# M05x_registers register map
File version: 0.1
CPU: 
Registers are 32-bit, read-write, reset 0x0 unless marked. A register's access mark holds for its fields unless they carry their own. Offsets are from the block's base; [hi:lo] are bit positions; lines under a group give offsets from that group; {n}, {i} and the like mark numbered series.

## CLK — Registers group
Base 0x50000200
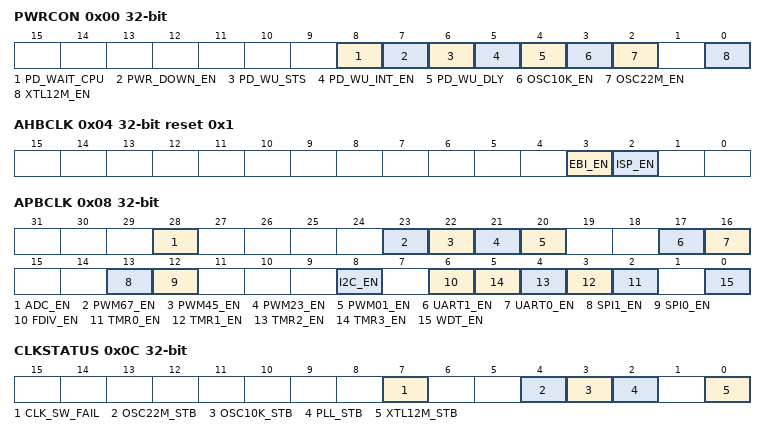
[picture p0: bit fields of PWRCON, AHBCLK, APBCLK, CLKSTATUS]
0x00 PWRCON (reset mask 0xFFFFFFF0) — System Power Down Control Register
  [8] PD_WAIT_CPU — This bit control the power down entry condition 1 = Chip entry power down mode when the both PWR_DOWN and CPU run WFI instruction. 0 = Chip entry power down mode when the PWR_DOWN bit is set to 1
  [7] PWR_DOWN_EN — System power down enable bit When set this bit "1", the chip power down mode is enabled and the chip power down active is depend on the PD_WAIT_CPU bit (a) if the PD_WAIT_CPU is "0" then the chip power down after the PWR_DOWN_EN bit set. (b) if the PD_WAIT_CPU is "1" then the chip keep active till the CPU sleep mode also active and then the chip power down When chip wake up from power down, this bit is auto cleared, user need to set this bit again for next power down. When in power down mode, external crystal (4~ 24MHz) and the 22.1184 MHz OSC will be disabled in this mode, but the 10 kHz OSC is not controlled by power down mode. When in power down mode, the PLL and system clock are disabled, and ignored the clock source selection. The clocks of peripheral are not controlled by power down mode, if the peripheral clock source is from 10 kHz oscillator. 1 = Chip enter the power down mode instant or wait CPU sleep command WFI 0 = Chip operate in normal mode or CPU in idle mode (sleep mode) because of WFI command
  [6] PD_WU_STS write-1-clears — Chip power down wake up status flag Set by "power down wake up", it indicates that resume from power down mode The flag is set if the GPIO(P0~P4), UART wakeup Write 1 to clear the bit Note: This bit is working only if PD_WU_INT_EN (PWRCON[5]) set to 1.
  [5] PD_WU_INT_EN — Power down mode wake Up Interrupt Enable 0 = Disable 1 = Enable. The interrupt will occur when Power down mode (Deep Sleep Mode) wakeup.
  [4] PD_WU_DLY — Enable the wake up delay counter. When the chip wakes up from power down mode, the clock control will delay certain clock cycles to wait system clock stable. The delayed clock cycle is 4096 clock cycles when chip work at external crystal (4 ~ 24MHz), and 256 clock cycles when chip work at 22.1184 MHz oscillator. 1 = Enable the clock cycle delay 0 = Disable the clock cycle delay
  [3] OSC10K_EN — Internal 10KHz Oscillator Control 1 = 10KHz Oscillation enable 0 = 10KHz Oscillation disable
  [2] OSC22M_EN — Internal 22.1184 MHz Oscillator Control 1 = 22.1184 MHz Oscillation enable 0 = 22.1184 MHz Oscillation disable
  [0] XTL12M_EN — External Crystal Oscillator Control The bit default value is set by flash controller user configuration register config0 [26:24]. When the default clock source is from external crystal. The bit is auto set to "1" 1 = Crystal oscillation enable 0 = Crystal oscillation disable
0x04 AHBCLK reset 0x1 — AHB Devices Clock Enable Control Register
  [3] EBI_EN — EBI Controller Clock Enable Control. 1 = To enable the EBI Controller clock. 0 = To disable the EBI Controller clock.
  [2] ISP_EN — Flash ISP Controller Clock Enable Control. 1 = To enable the Flash ISP controller clock. 0 = To disable the Flash ISP controller clock.
0x08 APBCLK (reset mask 0xFFFFFFF0) — APB Devices Clock Enable Control Register
  [28] ADC_EN — Analog-Digital-Converter (ADC) Clock Enable Control. 1 = Enable ADC clock 0 = Disable ADC clock
  [23] PWM67_EN — PWM_67 Clock Enable Control. 1 = Enable PWM67 clock 0 = Disable PWM67 clock
  [22] PWM45_EN — PWM_45 Clock Enable Control. 1 = Enable PWM45 clock 0 = Disable PWM45 clock
  [21] PWM23_EN — PWM_23 Clock Enable Control. 1 = Enable PWM23 clock 0 = Disable PWM23 clock
  [20] PWM01_EN — PWM_01 Clock Enable Control. 1 = Enable PWM01 clock 0 = Disable PWM01 clock
  [17] UART1_EN — UART1 Clock Enable Control. 1 = Enable UART1 clock 0 = Disable UART1 clock
  [16] UART0_EN — UART0 Clock Enable Control. 1 = Enable UART0 clock 0 = Disable UART0 clock
  [13] SPI1_EN — SPI1 Clock Enable Control. 0 = Disable SPI1 Clock 1 = Enable SPI1 Clock
  [12] SPI0_EN — SPI0 Clock Enable Control. 0 = Disable SPI0 Clock 1 = Enable SPI0 Clock
  [8] I2C_EN — I2C Clock Enable Control. 0 = Disable I2C Clock 1 = Enable I2C Clock
  [6] FDIV_EN — Clock Divider Clock Enable Control 0 = Disable FDIV Clock 1 = Enable FDIV Clock
  [n+2] TMR{n}_EN (n=0..3) — Timer{n} Clock Enable Control 0 = Disable Timer{n} Clock 1 = Enable Timer{n} Clock
  [0] WDT_EN — Watch Dog Timer Clock Enable. This bit is the protected bit, program this need a open lock sequence, write "59h","16h","88h" to address 0x5000_0100 to un-lock this bit. Reference the register REGWRPROT at address GCR_BA + 0x100 0 = Disable Watchdog Timer Clock 1 = Enable Watchdog Timer Clock
0x0C CLKSTATUS (reset mask 0xFFFFFF00) — Clock status monitor Register
  [7] CLK_SW_FAIL write-1-clears — Clock switch fail flag 1 = Clock switch fail 0 = Clock switch success This bit will be set when target switch clock source is not stable. Write 1 to clear this bit to zero.
  [4] OSC22M_STB ro — OSC22M clock source stable flag 1 = OSC22M clock is stable 0 = OSC22M clock is not stable or not enable
  [3] OSC10K_STB ro — OSC10K clock source stable flag 1 = OSC10K clock is stable 0 = OSC10K clock is not stable or not enable
  [2] PLL_STB ro — PLL clock source stable flag 1 = PLL clock is stable 0 = PLL clock is not stable or not enable
  [0] XTL12M_STB ro — XTL12M clock source stable flag 1 = External Crystal clock is stable 0 = External Crystal clock is not stable or not enable
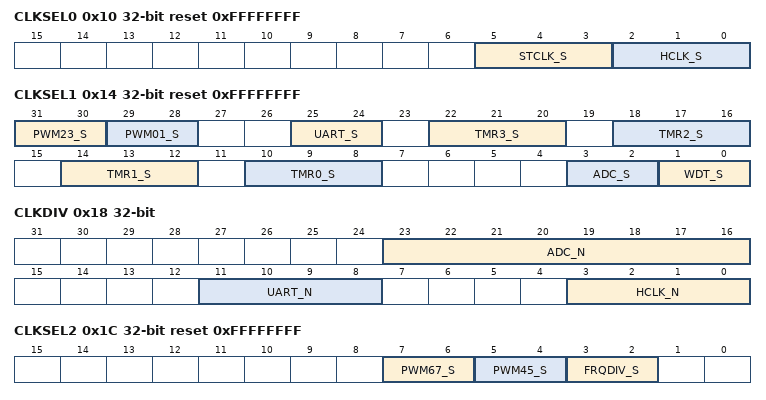
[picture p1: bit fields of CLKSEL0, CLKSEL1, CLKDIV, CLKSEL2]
0x10 CLKSEL0 reset 0xFFFFFFFF (reset mask 0xFFFFFFF0) — Clock Source Select Control Register 0
  [5:3] STCLK_S — MCU Cortex_M0 SysTick clock source select. These bits are protected bit, program this need an open lock sequence, write "59h","16h","88h" to address 0x5000_0100 to un-lock this bit. Reference the register REGWRPROT at address GCR_BA + 0x100 000 = Clock source from external crystal clock (4 ~ 24MHz) 010 = Clock source from external crystal clock (4 ~ 24MHz)/2 011 = clock source from HCLK/2 1xx = clock source from internal 22.1184 MHz oscillator clock/2
  [2:0] HCLK_S — HCLK clock source select. Note: Before clock switch the related clock sources (pre-select and new-select) must be turn on The 3-bit default value is reloaded with the value of Config0.CFOSC[26:24] in user configuration register in Flash controller by any reset. Therefore the default value is either 000b or 111b. These bits are protected bit, program this need an open lock sequence, write "59h","16h","88h" to address 0x5000_0100 to un-lock this bit. Reference the register REGWRPROT at address GCR_BA + 0x100 000 = clock source from external crystal clock (4 ~ 24MHz) 010 = clock source from PLL clock 011 = clock source from internal 10KHz oscillator clock 111 = clock source from internal 22.1184 MHz oscillator clock others = Reserved
0x14 CLKSEL1 reset 0xFFFFFFFF — Clock Source Select Control Register 1
  [31:30] PWM23_S — PWM2 and PWM3 clock source select. PWM2 and PWM3 uses the same Engine clock source, both of them with the same pre-scalar 00 = clock source from external crystal clock (4 ~ 24MHz) 10 = clock source from HCLK 11 = clock source from internal 22.1184 MHz oscillator clock
  [29:28] PWM01_S — PWM0 and PWM1 clock source select. PWM0 and PWM1 uses the same Engine clock source, both of them with the same pre-scalar 00 = clock source from external crystal clock (4 ~ 24MHz) 10 = clock source from HCLK 11 = clock source from internal 22.1184 MHz oscillator clock
  [25:24] UART_S — UART clock source select. 00 = clock source from external crystal clock (4 ~ 24MHz) 01 = clock source from PLL clock 1x = clock source from internal 22.1184 MHz oscillator clock
  [4n+10:4n+8] TMR{n}_S (n=0..3) — TIMER{n} clock source select. 000 = clock source from external crystal clock (4 ~ 24MHz) 010 = clock source from HCLK 011 = clock source from external trigger 1xx = clock source from internal 22.1184 MHz oscillator clock
  [3:2] ADC_S — ADC clock source select. 00 = clock source from external crystal clock (4 ~ 24MHz). 01 = clock source from PLL clock 1x = clock source from internal 22.1184 MHz oscillator clock
  [1:0] WDT_S — Watchdog Timer clock source select. These bits are protected bit, program this need a open lock sequence, write "59h","16h","88h" to address 0x5000_0100 to un-lock this bit. Reference the register REGWRPROT at address GCR_BA + 0x100 00 = clock source from external crystal clock (4 ~ 24MHz). 10 = clock source from HCLK/2048 clock 11 = clock source from internal 10KHz oscillator clock
0x18 CLKDIV — Clock Divider Number Register
  [23:16] ADC_N — ADC clock divide number from ADC clock source The ADC clock frequency = (ADC clock source frequency ) / (ADC_N + 1)
  [11:8] UART_N — UART clock divide number from UART clock source The UART clock frequency = (UART clock source frequency ) / (UART_N + 1)
  [3:0] HCLK_N — HCLK clock divide number from HCLK clock source The HCLK clock frequency = (HCLK clock source frequency) / (HCLK_N + 1)
0x1C CLKSEL2 reset 0xFFFFFFFF — Clock Source Select Control Register 2
  [7:6] PWM67_S — PWM6 and PWM7 clock source select. - PWM6 and PWM7 used the same Engine clock source, both of them with the same pre-scalar 00 = clock source from external crystal clock (4 ~ 24MHz) 10 = clock source from HCLK 11 = clock source from internal 22.1184 MHz oscillator clock
  [5:4] PWM45_S — PWM4 and PWM5 clock source select. - PWM4 and PWM5 used the same Engine clock source, both of them with the same pre-scalar 00 = clock source from external crystal clock (4 ~ 24MHz) 10 = clock source from HCLK 11 = clock source from internal 22.1184 MHz oscillator clock
  [3:2] FRQDIV_S — Clock Divider Clock Source Select 00 = clock source from external crystal clock (4 ~ 24MHz) 10 = clock source from HCLK 11 = clock source from internal 22.1184 MHz oscillator clock
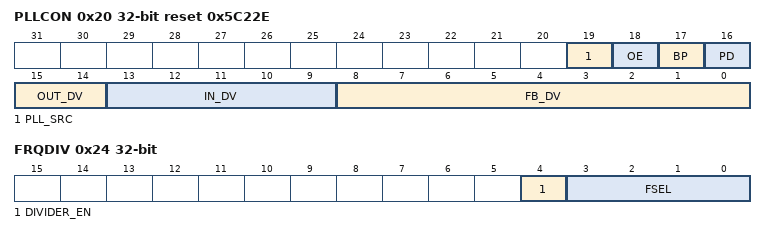
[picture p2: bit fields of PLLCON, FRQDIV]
0x20 PLLCON reset 0x5C22E (reset mask 0xFFFA3DD1) — PLL Control Register
  [19] PLL_SRC — PLL Source Clock Select 1 = PLL source clock from 22.1184 MHz oscillator 0 = PLL source clock from external crystal clock (4 ~ 24 MHz)
  [18] OE — PLL OE (FOUT enable) pin Control 0 = PLL FOUT enable 1 = PLL FOUT is fixed low
  [17] BP — PLL Bypass Control 0 = PLL is in normal mode (default) 1 = PLL clock output is same as clock input (XTALin)
  [16] PD — Power Down Mode. If set the IDLE bit "1" in PWRCON register, the PLL will enter power down mode too 0 = PLL is in normal mode (default) 1 = PLL is in power-down mode
  [15:14] OUT_DV — PLL Output Divider Control Pins (PLL_OD[1:0])
  [13:9] IN_DV — PLL Input Divider Control Pins (PLL_R[4:0])
  [8:0] FB_DV — PLL Feedback Divider Control Pins (PLL_F[8:0])
0x24 FRQDIV — Frequency Divider Control Register
  [4] DIVIDER_EN — Frequency Divider Enable Bit 0 = Disable Frequency Divider 1 = Enable Frequency Divider
  [3:0] FSEL — Divider Output Frequency Selection Bits The formula of output frequency is Fout = Fin/2(N+1), where Fin is the input clock frequency, Fout is the frequency of divider output clock, N is the 4-bit value of FSEL[3:0].
